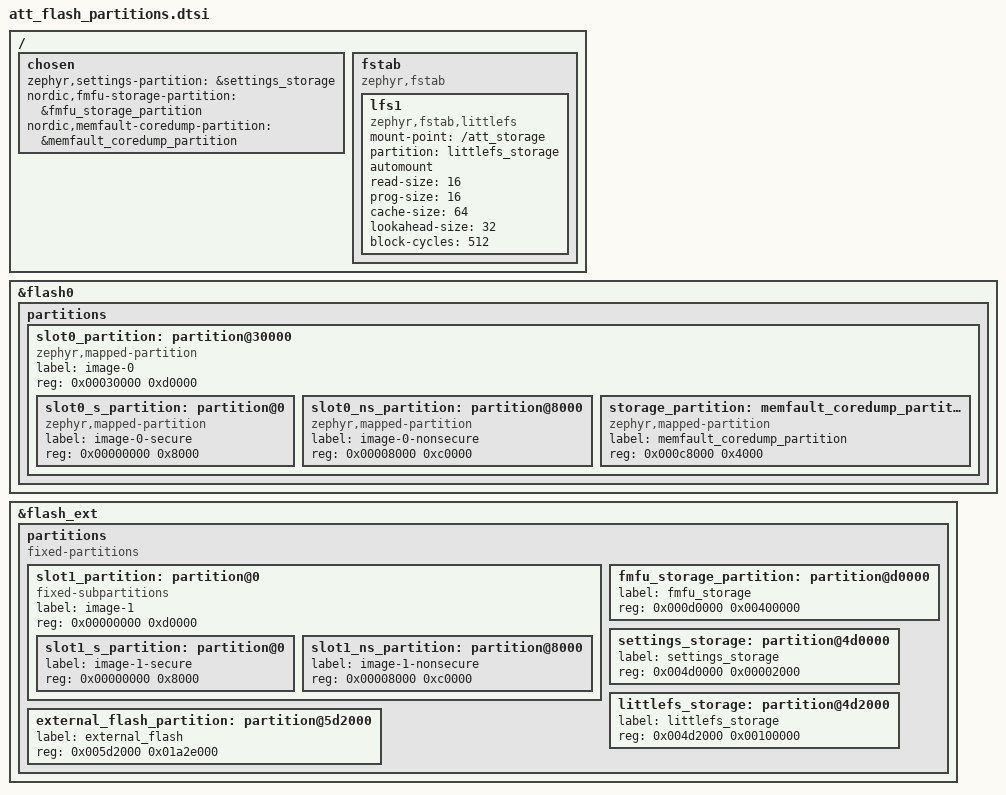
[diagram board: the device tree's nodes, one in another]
/*
 * Copyright (c) 2026 Nordic Semiconductor ASA
 *
 * SPDX-License-Identifier: LicenseRef-Nordic-5-Clause
 *
 * Flash layout (flash0, 1 MiB internal):
 *   0x00000000  b0_partition                  ( 32 KiB)  immutable bootloader
 *   0x00008000  s0_partition                  ( 80 KiB)  primary MCUboot
 *   0x0001c000  s1_partition                  ( 80 KiB)  secondary MCUboot
 *   0x00030000  slot0_partition (image-0)     (832 KiB)
 *     0x00000000  slot0_s_partition           ( 32 KiB)  TF-M secure
 *     0x00008000  slot0_ns_partition          (768 KiB)  Zephyr/app non-secure
 *     0x000c8000  memfault_coredump_partition ( 16 KiB)  persistent coredump
 *     0x000cc000  ( reserved for MCUboot )    ( 16 KiB)  trailer + move sector
 *
 * Flash layout (flash_ext, 32 MiB external):
 *   0x00000000  slot1_partition (image-1)     (832 KiB)  matches slot0 for MCUboot swap-move
 *     0x00000000  slot1_s_partition           ( 32 KiB)
 *     0x00008000  slot1_ns_partition          (768 KiB)
 *     0x000c8000  ( reserved, unused )        ( 32 KiB)  no coredump on secondary
 *   0x000d0000  fmfu_storage_partition        (  4 MiB)
 *   0x004d0000  settings_storage              (  8 KiB)
 *   0x004d2000  littlefs_storage              (  1 MiB)
 *   0x005d2000  external_flash_partition      (~26.2 MiB) free space
 *
 * NOTE: slot0/slot1 are sized 0xD0000 (832 KiB) to match the v1.0.0 - v1.4.x
 * PM-based layout that older FOTA images were built against. This is what
 * makes MCUboot's slot1 trailer land at the address that those older images
 * expect when they call boot_is_img_confirmed() / boot_write_img_confirmed()
 * after a swap, so the device reports nRF Cloud FOTA jobs as
 * "FOTA update completed successfully" rather than "without validation".
 *
 * The actual app+TFM image is limited to 768 KiB (slot0_s + slot0_ns) so
 * that the last 32 KiB of slot0 is unused by MCUboot's image swap. The first
 * 16 KiB of that tail is repurposed as the Memfault coredump partition (it
 * lives in memory-mapped internal flash, which is what the NCS Memfault
 * coredump driver - nrfx_nvmc-based - requires). The final 16 KiB is left
 * for MCUboot's own use (trailer ~6.2 KiB with CONFIG_BOOT_MAX_IMG_SECTORS=512
 * + one 4 KiB move sector + margin). swap-using-move only touches image
 * sectors plus the trailer/move sectors, so the coredump partition is
 * preserved across FOTA.
 *
 * If the app+TFM image ever grows past 768 KiB, the build will fail because
 * slot0_ns_partition is too small. If you change CONFIG_BOOT_MAX_IMG_SECTORS
 * or the swap algorithm, re-verify that the MCUboot reserved tail still fits.
 */

/delete-node/ &slot0_partition;
/delete-node/ &slot1_partition;
/delete-node/ &storage_partition;

/ {
	chosen {
		zephyr,settings-partition = &settings_storage;
		nordic,fmfu-storage-partition = &fmfu_storage_partition;
		nordic,memfault-coredump-partition = &memfault_coredump_partition;
	};

	fstab {
		compatible = "zephyr,fstab";
		lfs1: lfs1 {
			compatible = "zephyr,fstab,littlefs";
			mount-point = "/att_storage";
			partition = <&littlefs_storage>;
			automount;
			read-size = <16>;
			prog-size = <16>;
			cache-size = <64>;
			lookahead-size = <32>;
			block-cycles = <512>;
		};
	};
};

&flash0 {
	partitions {
		slot0_partition: partition@30000 {
			compatible = "zephyr,mapped-partition";
			label = "image-0";
			reg = <0x00030000 0xd0000>;
			ranges = <0x0 0x00030000 0xd0000>;
			#address-cells = <1>;
			#size-cells = <1>;

			slot0_s_partition: partition@0 {
				compatible = "zephyr,mapped-partition";
				label = "image-0-secure";
				reg = <0x00000000 0x8000>;
			};

			slot0_ns_partition: partition@8000 {
				compatible = "zephyr,mapped-partition";
				label = "image-0-nonsecure";
				reg = <0x00008000 0xc0000>;
			};

			storage_partition: memfault_coredump_partition: partition@c8000 {
				compatible = "zephyr,mapped-partition";
				label = "memfault_coredump_partition";
				reg = <0x000c8000 0x4000>;
			};
		};
	};
};

&flash_ext {
	status = "okay";

	partitions {
		compatible = "fixed-partitions";
		#address-cells = <1>;
		#size-cells = <1>;

		slot1_partition: partition@0 {
			compatible = "fixed-subpartitions";
			label = "image-1";
			reg = <0x00000000 0xd0000>;
			ranges = <0x0 0x00000 0xd0000>;
			#address-cells = <1>;
			#size-cells = <1>;

			slot1_s_partition: partition@0 {
				label = "image-1-secure";
				reg = <0x00000000 0x8000>;
			};

			slot1_ns_partition: partition@8000 {
				label = "image-1-nonsecure";
				reg = <0x00008000 0xc0000>;
			};
		};

		fmfu_storage_partition: partition@d0000 {
			label = "fmfu_storage";
			reg = <0x000d0000 0x00400000>;
		};

		settings_storage: partition@4d0000 {
			label = "settings_storage";
			reg = <0x004d0000 0x00002000>;
		};

		littlefs_storage: partition@4d2000 {
			label = "littlefs_storage";
			reg = <0x004d2000 0x00100000>;
		};

		external_flash_partition: partition@5d2000 {
			label = "external_flash";
			reg = <0x005d2000 0x01a2e000>;
		};
	};
};
